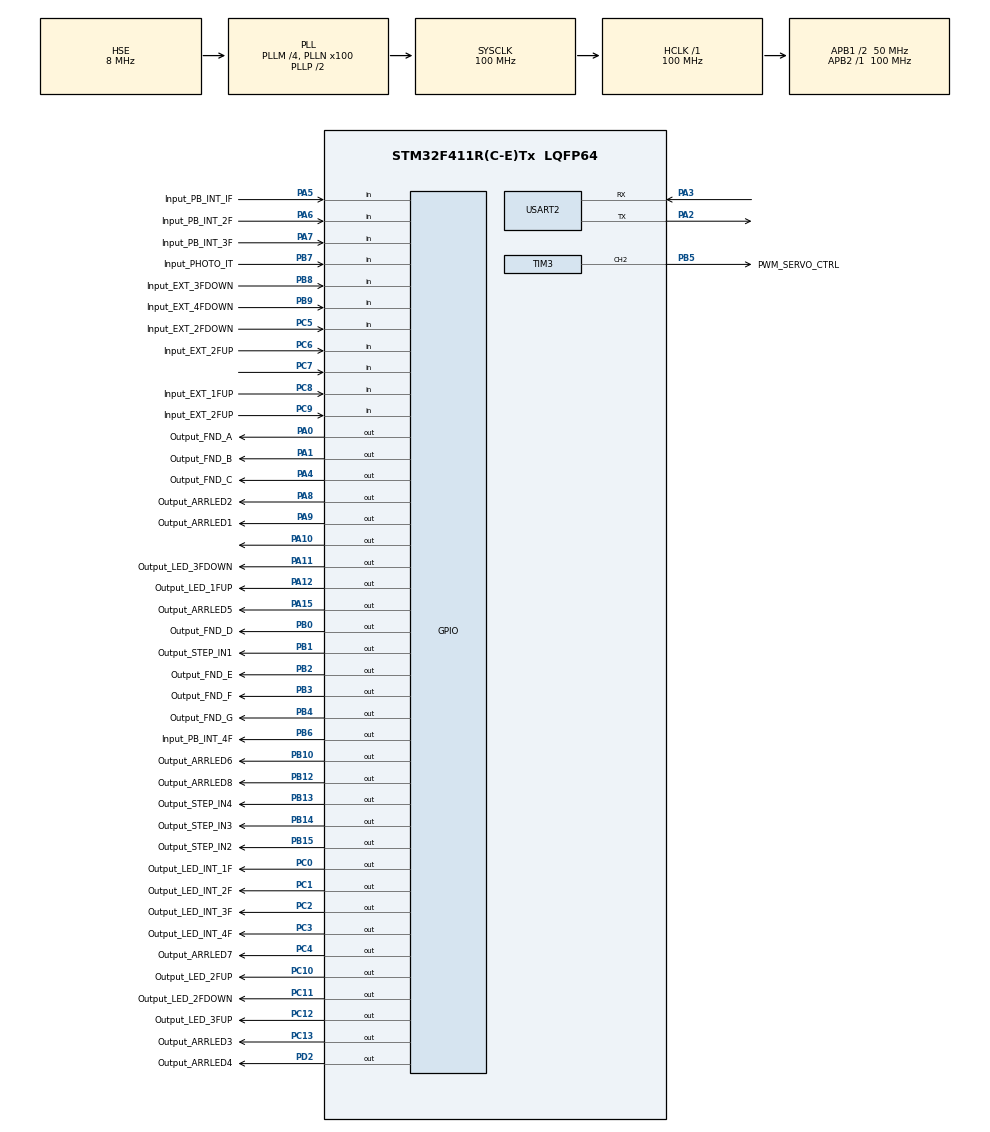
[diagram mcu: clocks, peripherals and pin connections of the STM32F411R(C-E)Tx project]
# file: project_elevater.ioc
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Mcu.Family=STM32F4
Mcu.Name=STM32F411R(C-E)Tx
Mcu.Package=LQFP64
NVIC.PriorityGroup=NVIC_PRIORITYGROUP_4
NVIC.TIM1_TRG_COM_TIM11_IRQn=true\:0\:0\:false\:false\:true\:true\:true\:true
NVIC.TIM3_IRQn=true\:0\:0\:false\:false\:true\:true\:true\:true
PA0-WKUP.GPIO_Label=Output_FND_A
PA0-WKUP.Signal=GPIO_Output
PA1.GPIO_Label=Output_FND_B
PA1.Signal=GPIO_Output
PA10.Signal=GPIO_Output
PA11.GPIO_Label=Output_LED_3FDOWN
PA11.Signal=GPIO_Output
PA12.GPIO_Label=Output_LED_1FUP
PA12.Signal=GPIO_Output
PA13.Mode=Serial_Wire
PA13.Signal=SYS_JTMS-SWDIO
PA14.Mode=Serial_Wire
PA14.Signal=SYS_JTCK-SWCLK
PA15.GPIO_Label=Output_ARRLED5
PA15.Signal=GPIO_Output
PA2.Mode=Asynchronous
PA2.Signal=USART2_TX
PA3.Mode=Asynchronous
PA3.Signal=USART2_RX
PA4.GPIO_Label=Output_FND_C
PA4.Signal=GPIO_Output
PA5.GPIO_Label=Input_PB_INT_IF
PA5.Signal=GPIO_Input
PA6.GPIO_Label=Input_PB_INT_2F
PA6.Signal=GPIO_Input
PA7.GPIO_Label=Input_PB_INT_3F
PA7.Signal=GPIO_Input
PA8.GPIO_Label=Output_ARRLED2
PA8.Signal=GPIO_Output
PA9.GPIO_Label=Output_ARRLED1
PA9.Signal=GPIO_Output
PB0.GPIO_Label=Output_FND_D
PB0.Signal=GPIO_Output
PB1.GPIO_Label=Output_STEP_IN1
PB1.Signal=GPIO_Output
PB10.GPIO_Label=Output_ARRLED6
PB10.Signal=GPIO_Output
PB12.GPIO_Label=Output_ARRLED8
PB12.Signal=GPIO_Output
PB13.GPIO_Label=Output_STEP_IN4
PB13.Signal=GPIO_Output
PB14.GPIO_Label=Output_STEP_IN3
PB14.Signal=GPIO_Output
PB15.GPIO_Label=Output_STEP_IN2
PB15.Signal=GPIO_Output
PB2.GPIO_Label=Output_FND_E
PB2.Signal=GPIO_Output
PB3.GPIO_Label=Output_FND_F
PB3.Signal=GPIO_Output
PB4.GPIO_Label=Output_FND_G
PB4.Signal=GPIO_Output
PB5.GPIO_Label=PWM_SERVO_CTRL
PB5.Signal=S_TIM3_CH2
PB6.GPIO_Label=Input_PB_INT_4F
PB6.Signal=GPIO_Output
PB7.GPIO_Label=Input_PHOTO_IT
PB7.Signal=GPIO_Input
PB8.GPIO_Label=Input_EXT_3FDOWN
PB8.Signal=GPIO_Input
PB9.GPIO_Label=Input_EXT_4FDOWN
PB9.Signal=GPIO_Input
PC0.GPIO_Label=Output_LED_INT_1F
PC0.Signal=GPIO_Output
PC1.GPIO_Label=Output_LED_INT_2F
PC1.Signal=GPIO_Output
PC10.GPIO_Label=Output_LED_2FUP
PC10.Signal=GPIO_Output
PC11.GPIO_Label=Output_LED_2FDOWN
PC11.Signal=GPIO_Output
PC12.GPIO_Label=Output_LED_3FUP
PC12.Signal=GPIO_Output
PC13-ANTI_TAMP.GPIO_Label=Output_ARRLED3
PC13-ANTI_TAMP.Signal=GPIO_Output
PC2.GPIO_Label=Output_LED_INT_3F
PC2.Signal=GPIO_Output
PC3.GPIO_Label=Output_LED_INT_4F
PC3.Signal=GPIO_Output
PC4.GPIO_Label=Output_ARRLED7
PC4.Signal=GPIO_Output
PC5.GPIO_Label=Input_EXT_2FDOWN
PC5.Signal=GPIO_Input
PC6.GPIO_Label=Input_EXT_2FUP
PC6.Signal=GPIO_Input
PC7.Signal=GPIO_Input
PC8.GPIO_Label=Input_EXT_1FUP
PC8.Signal=GPIO_Input
PC9.GPIO_Label=Input_EXT_2FUP
PC9.Signal=GPIO_Input
PD2.GPIO_Label=Output_ARRLED4
PD2.Signal=GPIO_Output
PH0\ -\ OSC_IN.Mode=HSE-External-Clock-Source
PH0\ -\ OSC_IN.Signal=RCC_OSC_IN
PH1\ -\ OSC_OUT.Mode=HSE-External-Clock-Source
PH1\ -\ OSC_OUT.Signal=RCC_OSC_OUT
ProjectManager.HeapSize=0x200
ProjectManager.StackSize=0x400
ProjectManager.TargetToolchain=STM32CubeIDE
RCC.48MHZClocksFreq_Value=50000000
RCC.AHBFreq_Value=100000000
RCC.APB1CLKDivider=RCC_HCLK_DIV2
RCC.APB1Freq_Value=50000000
RCC.APB1TimFreq_Value=100000000
RCC.APB2Freq_Value=100000000
RCC.APB2TimFreq_Value=100000000
RCC.CortexFreq_Value=100000000
RCC.HCLKFreq_Value=100000000
RCC.HSE_VALUE=8000000
RCC.HSI_VALUE=16000000
RCC.LSE_VALUE=32768
RCC.PLLM=4
RCC.PLLN=100
RCC.PLLSourceVirtual=RCC_PLLSOURCE_HSE
RCC.SYSCLKFreq_VALUE=100000000
RCC.SYSCLKSource=RCC_SYSCLKSOURCE_PLLCLK
RCC.VCOOutputFreq_Value=200000000
SH.S_TIM3_CH2.0=TIM3_CH2,PWM Generation2 CH2
TIM11.Prescaler=100-1
TIM3.Channel-PWM\ Generation2\ CH2=TIM_CHANNEL_2
TIM3.Period=2000-1
TIM3.Prescaler=1000-1
TIM3.Pulse-PWM\ Generation2\ CH2=500
USART2.VirtualMode=VM_ASYNC
VP_TIM11_VS_ClockSourceINT.Mode=Enable_Timer
VP_TIM3_VS_ClockSourceINT.Mode=Internal
board=custom

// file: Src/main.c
/* USER CODE BEGIN Header */
/**
 ******************************************************************************
 * @file           : main.c
 * @brief          : Main program body
 ******************************************************************************
 */
/* USER CODE END Header */
#include "main.h"
#include "tim.h"
#include "usart.h"
#include "gpio.h"

/* USER CODE BEGIN Includes */
#include "elevator_ctrl.h"
/* USER CODE END Includes */

void SystemClock_Config(void);

int main(void)
{

  /* MCU Configuration--------------------------------------------------------*/

  /* Reset of all peripherals, Initializes the Flash interface and the Systick. */
  HAL_Init();

  /* Configure the system clock */
  SystemClock_Config();

  /* Initialize all configured peripherals */
  MX_GPIO_Init();
  MX_TIM3_Init();
  MX_USART2_UART_Init();
  MX_TIM11_Init();
  /* USER CODE BEGIN 2 */
  ElevatorSystem_Init(&htim11);

  /* USER CODE END 2 */

  /* Infinite loop */
  /* USER CODE BEGIN WHILE */
  while (1)
  {
	  ElevatorSystem_Run();
//	  ElevatorSystem_PowerTest();
    /* USER CODE END WHILE */

  }
}

void SystemClock_Config(void)
{
  RCC_OscInitTypeDef RCC_OscInitStruct = {0};
  RCC_ClkInitTypeDef RCC_ClkInitStruct = {0};

  /** Configure the main internal regulator output voltage
  */
  __HAL_RCC_PWR_CLK_ENABLE();
  __HAL_PWR_VOLTAGESCALING_CONFIG(PWR_REGULATOR_VOLTAGE_SCALE1);

  /** Initializes the RCC Oscillators according to the specified parameters
  * in the RCC_OscInitTypeDef structure.
  */
  RCC_OscInitStruct.OscillatorType = RCC_OSCILLATORTYPE_HSE;
  RCC_OscInitStruct.HSEState = RCC_HSE_BYPASS;
  RCC_OscInitStruct.PLL.PLLState = RCC_PLL_ON;
  RCC_OscInitStruct.PLL.PLLSource = RCC_PLLSOURCE_HSE;
  RCC_OscInitStruct.PLL.PLLM = 4;
  RCC_OscInitStruct.PLL.PLLN = 100;
  RCC_OscInitStruct.PLL.PLLP = RCC_PLLP_DIV2;
  RCC_OscInitStruct.PLL.PLLQ = 4;
  if (HAL_RCC_OscConfig(&RCC_OscInitStruct) != HAL_OK)
  {
    Error_Handler();
  }

  /** Initializes the CPU, AHB and APB buses clocks
  */
  RCC_ClkInitStruct.ClockType = RCC_CLOCKTYPE_HCLK|RCC_CLOCKTYPE_SYSCLK
                              |RCC_CLOCKTYPE_PCLK1|RCC_CLOCKTYPE_PCLK2;
  RCC_ClkInitStruct.SYSCLKSource = RCC_SYSCLKSOURCE_PLLCLK;
  RCC_ClkInitStruct.AHBCLKDivider = RCC_SYSCLK_DIV1;
  RCC_ClkInitStruct.APB1CLKDivider = RCC_HCLK_DIV2;
  RCC_ClkInitStruct.APB2CLKDivider = RCC_HCLK_DIV1;

  if (HAL_RCC_ClockConfig(&RCC_ClkInitStruct, FLASH_LATENCY_3) != HAL_OK)
  {
    Error_Handler();
  }
}

void Error_Handler(void)
{
  __disable_irq();
  while (1)
  {
  }
}
